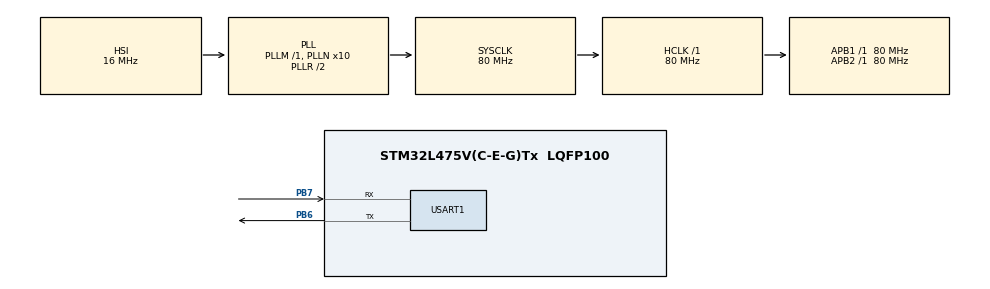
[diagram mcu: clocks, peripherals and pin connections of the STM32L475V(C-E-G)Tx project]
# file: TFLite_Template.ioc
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Mcu.Family=STM32L4
Mcu.Name=STM32L475V(C-E-G)Tx
Mcu.Package=LQFP100
NVIC.PriorityGroup=NVIC_PRIORITYGROUP_4
PB6.Mode=Asynchronous
PB6.Signal=USART1_TX
PB7.Mode=Asynchronous
PB7.Signal=USART1_RX
ProjectManager.HeapSize=0x2000
ProjectManager.StackSize=0x4000
ProjectManager.TargetToolchain=STM32CubeIDE
RCC.ADCFreq_Value=64000000
RCC.AHBFreq_Value=80000000
RCC.APB1Freq_Value=80000000
RCC.APB1TimFreq_Value=80000000
RCC.APB2Freq_Value=80000000
RCC.APB2TimFreq_Value=80000000
RCC.CortexFreq_Value=80000000
RCC.HCLKFreq_Value=80000000
RCC.HSE_VALUE=8000000
RCC.HSI_VALUE=16000000
RCC.LSE_VALUE=32768
RCC.MSI_VALUE=4000000
RCC.PLLN=10
RCC.PLLSourceVirtual=RCC_PLLSOURCE_HSI
RCC.SYSCLKFreq_VALUE=80000000
RCC.SYSCLKSource=RCC_SYSCLKSOURCE_PLLCLK
RCC.USBFreq_Value=64000000
RCC.VCOOutputFreq_Value=160000000
STMicroelectronics.X-CUBE-AI.5.0.0.ActivationBufferSizeList=13520
STMicroelectronics.X-CUBE-AI.5.0.0.ApplicationCcArtificialOoIntelligenceJjApplication=ApplicationTemplate
STMicroelectronics.X-CUBE-AI.5.0.0.HeapSize=0x2000
STMicroelectronics.X-CUBE-AI.5.0.0.InternalRamActivationBufferMaxSize=AI_TFLITE_DATA_ACTIVATIONS_SIZE
STMicroelectronics.X-CUBE-AI.5.0.0.LatestDirectoryUsed-b02b976feafcb612b77cf83a168f463d7716c38a5550ec034e8801d6de096f02=C\:\\Users\\Marco\\Documents\\GitHub\\Embedded-neural-net-traffic-sign-recognition\\Models
STMicroelectronics.X-CUBE-AI.5.0.0.MaximumNumberOfInputLayer=1
STMicroelectronics.X-CUBE-AI.5.0.0.MaximumNumberOfOutputLayer=1
STMicroelectronics.X-CUBE-AI.5.0.0.MaximumSizeOfInputLayer=1024
STMicroelectronics.X-CUBE-AI.5.0.0.MaximumSizeOfOutputLayer=43
STMicroelectronics.X-CUBE-AI.5.0.0.ModelActualCompression-b02b976feafcb612b77cf83a168f463d7716c38a5550ec034e8801d6de096f02=0.0
STMicroelectronics.X-CUBE-AI.5.0.0.ModelCompression-b02b976feafcb612b77cf83a168f463d7716c38a5550ec034e8801d6de096f02=1
STMicroelectronics.X-CUBE-AI.5.0.0.ModelFlashOccupation-b02b976feafcb612b77cf83a168f463d7716c38a5550ec034e8801d6de096f02=104808
STMicroelectronics.X-CUBE-AI.5.0.0.ModelHashList=b02b976feafcb612b77cf83a168f463d7716c38a5550ec034e8801d6de096f02
STMicroelectronics.X-CUBE-AI.5.0.0.ModelKind-b02b976feafcb612b77cf83a168f463d7716c38a5550ec034e8801d6de096f02=TFLITE
STMicroelectronics.X-CUBE-AI.5.0.0.ModelMacc-b02b976feafcb612b77cf83a168f463d7716c38a5550ec034e8801d6de096f02=1496917
STMicroelectronics.X-CUBE-AI.5.0.0.ModelName-b02b976feafcb612b77cf83a168f463d7716c38a5550ec034e8801d6de096f02=tflite
STMicroelectronics.X-CUBE-AI.5.0.0.ModelNameList=tflite
STMicroelectronics.X-CUBE-AI.5.0.0.ModelRamOccupation-b02b976feafcb612b77cf83a168f463d7716c38a5550ec034e8801d6de096f02=13520
STMicroelectronics.X-CUBE-AI.5.0.0.ModelStructureFile-b02b976feafcb612b77cf83a168f463d7716c38a5550ec034e8801d6de096f02=C\:\\Users\\Marco\\Documents\\GitHub\\Embedded-neural-net-traffic-sign-recognition\\Models\\model_pq_w_a.tflite
STMicroelectronics.X-CUBE-AI.5.0.0.ModelType-b02b976feafcb612b77cf83a168f463d7716c38a5550ec034e8801d6de096f02=Saved model
STMicroelectronics.X-CUBE-AI.5.0.0.NNModelInformation_AchievedCompression-b02b976feafcb612b77cf83a168f463d7716c38a5550ec034e8801d6de096f02=0.0
STMicroelectronics.X-CUBE-AI.5.0.0.NNModelInformation_CompressionFactor-b02b976feafcb612b77cf83a168f463d7716c38a5550ec034e8801d6de096f02=0.004658653016621614
STMicroelectronics.X-CUBE-AI.5.0.0.NNModelInformation_EvaluationStatus-b02b976feafcb612b77cf83a168f463d7716c38a5550ec034e8801d6de096f02=NOT EVALUATED
STMicroelectronics.X-CUBE-AI.5.0.0.NNModelInformation_HeapSizeNeeded-b02b976feafcb612b77cf83a168f463d7716c38a5550ec034e8801d6de096f02=3072
STMicroelectronics.X-CUBE-AI.5.0.0.NNModelInformation_ModelInSizeByName-b02b976feafcb612b77cf83a168f463d7716c38a5550ec034e8801d6de096f02={input_0\=1024}
STMicroelectronics.X-CUBE-AI.5.0.0.NNModelInformation_ModelMacc-b02b976feafcb612b77cf83a168f463d7716c38a5550ec034e8801d6de096f02=1496917
STMicroelectronics.X-CUBE-AI.5.0.0.NNModelInformation_ModelName-b02b976feafcb612b77cf83a168f463d7716c38a5550ec034e8801d6de096f02=tflite
STMicroelectronics.X-CUBE-AI.5.0.0.NNModelInformation_ModelOutSizeByName-b02b976feafcb612b77cf83a168f463d7716c38a5550ec034e8801d6de096f02={nl_14\=43}
STMicroelectronics.X-CUBE-AI.5.0.0.NNModelInformation_ModelRam-b02b976feafcb612b77cf83a168f463d7716c38a5550ec034e8801d6de096f02=13520
STMicroelectronics.X-CUBE-AI.5.0.0.NNModelInformation_ModelRom-b02b976feafcb612b77cf83a168f463d7716c38a5550ec034e8801d6de096f02=104808
STMicroelectronics.X-CUBE-AI.5.0.0.NNModelInformation_ModelSize-b02b976feafcb612b77cf83a168f463d7716c38a5550ec034e8801d6de096f02=104322
STMicroelectronics.X-CUBE-AI.5.0.0.NNModelInformation_NbOfParameters-b02b976feafcb612b77cf83a168f463d7716c38a5550ec034e8801d6de096f02=103413
STMicroelectronics.X-CUBE-AI.5.0.0.StackSize=0x4000
STMicroelectronics.X-CUBE-AI.5.0.0.WorkingBufferStartAddrList=0xFFFFFFFF
STMicroelectronics.X-CUBE-AI.5.0.0.XAaCUBEAaAICcArtificialOoIntelligenceJjCore=true
USART1.VirtualMode-Asynchronous=VM_ASYNC
VP_CRC_VS_CRC.Mode=CRC_Activate
VP_STMicroelectronics.X-CUBE-AI_VS_ArtificialOoIntelligenceJjApplication_5.0.0.Mode=ArtificialOoIntelligenceJjApplication
VP_STMicroelectronics.X-CUBE-AI_VS_ArtificialOoIntelligenceJjXAaCUBEAaAI_5.0.0.Mode=ArtificialOoIntelligenceJjXAaCUBEAaAI
board=custom

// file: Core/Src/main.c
/* USER CODE BEGIN Header */
/**
  ******************************************************************************
  * @file           : main.c
  * @brief          : Main program body
  ******************************************************************************
  * @attention
  *
  * <h2><center>&copy; Copyright (c) 2020 STMicroelectronics.
  * All rights reserved.</center></h2>
  *
  * This software component is licensed by ST under BSD 3-Clause license,
  * the "License"; You may not use this file except in compliance with the
  * License. You may obtain a copy of the License at:
  *                        opensource.org/licenses/BSD-3-Clause
  *
  ******************************************************************************
  */
/* USER CODE END Header */

#include "main.h"
#include "app_x-cube-ai.h"

CRC_HandleTypeDef hcrc;

UART_HandleTypeDef huart1;

void SystemClock_Config(void);
static void MX_GPIO_Init(void);
static void MX_USART1_UART_Init(void);
static void MX_CRC_Init(void);

int main(void)
{

  /* MCU Configuration--------------------------------------------------------*/

  /* Reset of all peripherals, Initializes the Flash interface and the Systick. */
  HAL_Init();

  /* Configure the system clock */
  SystemClock_Config();

  /* Initialize all configured peripherals */
  MX_GPIO_Init();
  MX_USART1_UART_Init();
  MX_CRC_Init();
  MX_X_CUBE_AI_Init();
  /* USER CODE BEGIN 2 */
  //char buffer[50] = {};
  //sprintf(buffer, "Starting the App\n");
  //HAL_UART_Transmit(&huart1, buffer, strlen(buffer), 1000);

  /* USER CODE END 2 */

  /* Infinite loop */
  while (1)
  {

  //MX_X_CUBE_AI_Process();
    /* USER CODE BEGIN 3 */
	  //inference_w(huart1);
	  inference_w_a(huart1);
  }
  /* USER CODE END 3 */
}

void SystemClock_Config(void)
{
  RCC_OscInitTypeDef RCC_OscInitStruct = {0};
  RCC_ClkInitTypeDef RCC_ClkInitStruct = {0};
  RCC_PeriphCLKInitTypeDef PeriphClkInit = {0};

  /** Initializes the CPU, AHB and APB busses clocks
  */
  RCC_OscInitStruct.OscillatorType = RCC_OSCILLATORTYPE_HSI;
  RCC_OscInitStruct.HSIState = RCC_HSI_ON;
  RCC_OscInitStruct.HSICalibrationValue = RCC_HSICALIBRATION_DEFAULT;
  RCC_OscInitStruct.PLL.PLLState = RCC_PLL_ON;
  RCC_OscInitStruct.PLL.PLLSource = RCC_PLLSOURCE_HSI;
  RCC_OscInitStruct.PLL.PLLM = 1;
  RCC_OscInitStruct.PLL.PLLN = 10;
  RCC_OscInitStruct.PLL.PLLP = RCC_PLLP_DIV7;
  RCC_OscInitStruct.PLL.PLLQ = RCC_PLLQ_DIV2;
  RCC_OscInitStruct.PLL.PLLR = RCC_PLLR_DIV2;
  if (HAL_RCC_OscConfig(&RCC_OscInitStruct) != HAL_OK)
  {
    Error_Handler();
  }
  /** Initializes the CPU, AHB and APB busses clocks
  */
  RCC_ClkInitStruct.ClockType = RCC_CLOCKTYPE_HCLK|RCC_CLOCKTYPE_SYSCLK
                              |RCC_CLOCKTYPE_PCLK1|RCC_CLOCKTYPE_PCLK2;
  RCC_ClkInitStruct.SYSCLKSource = RCC_SYSCLKSOURCE_PLLCLK;
  RCC_ClkInitStruct.AHBCLKDivider = RCC_SYSCLK_DIV1;
  RCC_ClkInitStruct.APB1CLKDivider = RCC_HCLK_DIV1;
  RCC_ClkInitStruct.APB2CLKDivider = RCC_HCLK_DIV1;

  if (HAL_RCC_ClockConfig(&RCC_ClkInitStruct, FLASH_LATENCY_4) != HAL_OK)
  {
    Error_Handler();
  }
  PeriphClkInit.PeriphClockSelection = RCC_PERIPHCLK_USART1;
  PeriphClkInit.Usart1ClockSelection = RCC_USART1CLKSOURCE_PCLK2;
  if (HAL_RCCEx_PeriphCLKConfig(&PeriphClkInit) != HAL_OK)
  {
    Error_Handler();
  }
  /** Configure the main internal regulator output voltage
  */
  if (HAL_PWREx_ControlVoltageScaling(PWR_REGULATOR_VOLTAGE_SCALE1) != HAL_OK)
  {
    Error_Handler();
  }
}

static void MX_CRC_Init(void)
{

  hcrc.Instance = CRC;
  hcrc.Init.DefaultPolynomialUse = DEFAULT_POLYNOMIAL_ENABLE;
  hcrc.Init.DefaultInitValueUse = DEFAULT_INIT_VALUE_ENABLE;
  hcrc.Init.InputDataInversionMode = CRC_INPUTDATA_INVERSION_NONE;
  hcrc.Init.OutputDataInversionMode = CRC_OUTPUTDATA_INVERSION_DISABLE;
  hcrc.InputDataFormat = CRC_INPUTDATA_FORMAT_BYTES;
  if (HAL_CRC_Init(&hcrc) != HAL_OK)
  {
    Error_Handler();
  }

}

static void MX_USART1_UART_Init(void)
{

  huart1.Instance = USART1;
  huart1.Init.BaudRate = 115200;
  huart1.Init.WordLength = UART_WORDLENGTH_8B;
  huart1.Init.StopBits = UART_STOPBITS_1;
  huart1.Init.Parity = UART_PARITY_NONE;
  huart1.Init.Mode = UART_MODE_TX_RX;
  huart1.Init.HwFlowCtl = UART_HWCONTROL_NONE;
  huart1.Init.OverSampling = UART_OVERSAMPLING_16;
  huart1.Init.OneBitSampling = UART_ONE_BIT_SAMPLE_DISABLE;
  huart1.AdvancedInit.AdvFeatureInit = UART_ADVFEATURE_NO_INIT;
  if (HAL_UART_Init(&huart1) != HAL_OK)
  {
    Error_Handler();
  }

}

static void MX_GPIO_Init(void)
{

  /* GPIO Ports Clock Enable */
  __HAL_RCC_GPIOB_CLK_ENABLE();

}

void Error_Handler(void)
{
}

/************************ (C) COPYRIGHT STMicroelectronics *****END OF FILE****/
